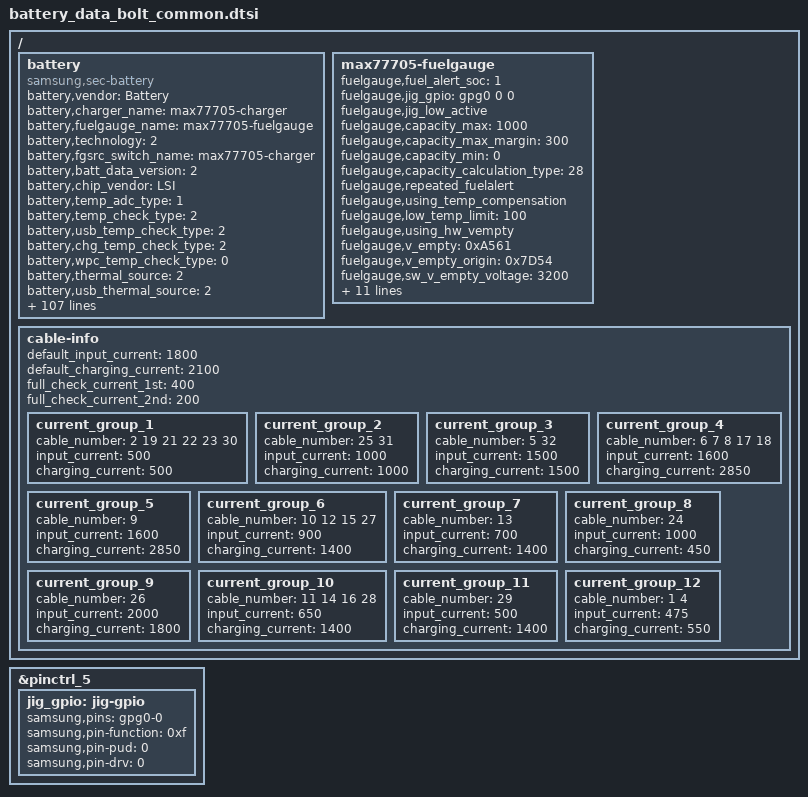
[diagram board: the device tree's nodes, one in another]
/*
 * SAMSUNG UNIVERSAL9820 board device tree source
 *
 * Copyright (c) 2018 Samsung Electronics Co., Ltd.
 *		http://www.samsung.com
 *
 * This program is free software; you can redistribute it and/or modify
 * it under the terms of the GNU General Public License version 2 as
 * published by the Free Software Foundation.
 */

/ {
	fragment@battery {
		target-path = "/";
		__overlay__ {
			battery {
				status = "okay";
				compatible = "samsung,sec-battery";

				pinctrl-names = "default";
				/* battery,irq_gpio = <&gpa1 6 0>; */

				battery,vendor = "Battery";
				battery,charger_name = "max77705-charger";
				battery,fuelgauge_name = "max77705-fuelgauge";
				battery,technology = <2>; /* POWER_SUPPLY_TECHNOLOGY_LION */
				battery,fgsrc_switch_name = "max77705-charger"; /* Fuelgauge voltage source */

				battery,batt_data_version = <2>;

				battery,chip_vendor = "LSI";
				battery,temp_adc_type = <1>; /* SEC_BATTERY_ADC_TYPE_AP */

				battery,temp_check_type = <2>; /* SEC_BATTERY_TEMP_CHECK_NONE */
				battery,usb_temp_check_type = <2>;
				battery,chg_temp_check_type = <2>;
				battery,wpc_temp_check_type = <0>;

				battery,thermal_source = <2>; /* SEC_BATTERY_THERMAL_SOURCE_ADC */
				battery,usb_thermal_source = <2>; /* SEC_BATTERY_THERMAL_SOURCE_ADC */
				battery,chg_thermal_source = <2>; /* SEC_BATTERY_THERMAL_SOURCE_ADC */

				battery,polling_time = <10 30 30 30 3600>;

				battery,temp_table_adc = <262 311 370 436 509 591 695 818 877 1058 1224 1404
								1604 1814 2044 2288 2493 2675 2888 3036 3387 3525 3596>;
				battery,temp_table_data = <900 850 800 750 700 650 600 550 500 450 400 350
								300 250 200 150 100 50 0 (-50) (-100) (-150) (-200)>;

				battery,usb_temp_table_adc = <267 319 379 449 527 615 724 850 946 1126 1304 1484
								1684 1894 2137 2362 2566 2735 2947 3042 3297 3419 3484>;
				battery,usb_temp_table_data = <900 850 800 750 700 650 600 550 500 450 400 350
								300 250 200 150 100 50 0 (-50) (-100) (-150) (-200)>;

				battery,chg_temp_table_adc = <255 303 362 428 500 579 679 801 898 1082 1344 1524
								1724 1934 2088 2336 2536 2715 2932 3065 3357 3495 3584>;
				battery,chg_temp_table_data = <900 850 800 750 700 650 600 550 500 450 400 350
								300 250 200 150 100 50 0 (-50) (-100) (-150) (-200)>;

				battery,adc_check_count = <5>;

				battery,cable_check_type = <4>; /* SEC_BATTERY_CABLE_CHECK_PSY */
				battery,cable_source_type = <1>; /* SEC_BATTERY_CABLE_SOURCE_EXTERNAL */
				battery,polling_type = <1>; /* SEC_BATTERY_MONITOR_ALARM */
				battery,monitor_initial_count = <0>;

				battery,battery_check_type = <0>; /* SEC_BATTERY_CHECK_NONE */
				battery,check_count = <0>;
				battery,check_adc_max = <1440>;
				battery,check_adc_min = <0>;

				battery,ovp_uvlo_check_type = <3>; /* SEC_BATTERY_OVP_UVLO_CHGPOLLING */

				battery,temp_check_count = <1>;
				battery,temp_highlimit_threshold_event = <800>;
				battery,temp_highlimit_recovery_event = <750>;
				battery,temp_high_threshold_event = <500>;
				battery,temp_high_recovery_event = <450>;
				battery,temp_low_threshold_event = <0>;
				battery,temp_low_recovery_event = <50>;
				battery,temp_highlimit_threshold_normal = <800>;
				battery,temp_highlimit_recovery_normal = <750>;
				battery,temp_high_threshold_normal = <500>;
				battery,temp_high_recovery_normal = <450>;
				battery,temp_low_threshold_normal = <0>;
				battery,temp_low_recovery_normal = <50>;
				battery,temp_highlimit_threshold_lpm = <800>;
				battery,temp_highlimit_recovery_lpm = <750>;
				battery,temp_high_threshold_lpm = <500>;
				battery,temp_high_recovery_lpm = <450>;
				battery,temp_low_threshold_lpm = <0>;
				battery,temp_low_recovery_lpm = <50>;
				battery,full_check_type = <7>; /* SEC_BATTERY_FULLCHARGED_CHGPSY */
				battery,full_check_type_2nd = <7>; /* SEC_BATTERY_FULLCHARGED_CHGPSY */
				battery,full_check_count = <1>;
				battery,chg_gpio_full_check = <0>;
				battery,chg_polarity_full_check = <1>;

				battery,chg_high_temp = <460>;
				battery,chg_high_temp_recovery = <440>;
				battery,chg_input_limit_current = <1000>;
				battery,chg_charging_limit_current = <1500>;

				battery,mix_high_temp = <420>;
				battery,mix_high_chg_temp = <500>;
				battery,mix_high_temp_recovery = <390>;

				/* SEC_BATTERY_FULL_CONDITION_NOTIMEFULL | SEC_BATTERY_FULL_CONDITION_VCELL */
				battery,full_condition_type = <9>;
				battery,full_condition_soc = <93>;
				battery,full_condition_vcell = <4250>;

				battery,recharge_check_count = <1>;
				battery,recharge_condition_type = <4>; /* SEC_BATTERY_RECHARGE_CONDITION_VCELL */
				battery,recharge_condition_soc = <98>;
				battery,recharge_condition_vcell = <4280>;

				battery,charging_total_time = <14400>;
				battery,hv_charging_total_time = <10800>;
				battery,normal_charging_total_time = <18000>;
				battery,usb_charging_total_time = <36000>;
				battery,recharging_total_time = <5400>;
				battery,charging_reset_time = <0>;

				battery,chg_float_voltage = <4350>;

				battery,swelling_high_temp_block = <410>;
				battery,swelling_high_temp_recov = <390>;
				battery,swelling_low_temp_block_1st = <150>;
				battery,swelling_low_temp_recov_1st = <200>;
				battery,swelling_low_temp_block_2nd = <50>;
				battery,swelling_low_temp_recov_2nd = <100>;

				battery,swelling_low_temp_current = <950>;	/* 0.3C */
				battery,swelling_low_temp_current_2nd = <950>;	/* 0.1C */
				battery,swelling_low_temp_topoff = <200>;	/* 0.05C */
				battery,swelling_high_temp_current = <1400>;	/* 0.45C */
				battery,swelling_high_temp_topoff = <200>;	/* 0.05C */

				battery,swelling_drop_float_voltage = <4150>;
				battery,swelling_high_rechg_voltage = <4000>;
				battery,swelling_low_rechg_voltage = <4000>;
				battery,wa_float_voltage = <4050>;

				battery,siop_input_limit_current = <1200>;
				battery,siop_charging_limit_current = <1000>;
				battery,siop_hv_input_limit_current = <500>;
				battery,siop_hv_charging_limit_current = <1000>;

				battery,ttf_hv_charge_current = <2850>;

				battery,pd_charging_charge_power = <15000>;
				battery,max_charging_current = <2850>;
				battery,battery_full_capacity = <4000>;

				/* cycle, chg_float_voltage, recharge_condition_vcell, full_condition_vcell, full_condition_soc */
				battery,age_data = <0 4350 4280 4250 93
					300 4330 4260 4230 92
					400 4310 4240 4210 91
					700 4290 4220 4190 90
					1000 4240 4170 4140 89>;

				battery,pre_afc_input_current = <500>; /* mA */
				battery,prepare_ta_delay = <0>; /* msec */

				battery,max_input_voltage = <9000>; /* mV */
				battery,max_input_current = <3000>;  /* mA */

				battery,enable_sysovlo_irq;

				battery,standard_curr = <2850>;
				battery,expired_time = <10800>;
				battery,recharging_expired_time = <5400>;

				battery,cisd_max_voltage_thr = <4400>; /* battery ovp detection voltage */

				battery,cisd_alg_index = <7>;

				io-channels = <&exynos_adc 4>, <&exynos_adc 3>, <&exynos_adc 1>;
				io-channel-names = "adc-temp", "adc-chg-temp", "adc-usb-temp";
				#io-channel-cells = <5>;
				io-channel-ranges;
			};

			max77705-fuelgauge {
				/* for 4000mAh battery */
				status = "okay";
				fuelgauge,fuel_alert_soc = <1>;
				fuelgauge,jig_gpio = <&gpg0 0 0>;
				fuelgauge,jig_low_active;
				fuelgauge,capacity_max = <1000>;
				fuelgauge,capacity_max_margin = <300>;
				fuelgauge,capacity_min = <0>;
				fuelgauge,capacity_calculation_type = <28>;
				fuelgauge,repeated_fuelalert;
				fuelgauge,using_temp_compensation;
				fuelgauge,low_temp_limit = <100>;
				fuelgauge,using_hw_vempty;
				fuelgauge,v_empty = <0xA561>; /* Empty: 3350mV, Recover: 3920mV */
				fuelgauge,v_empty_origin = <0x7D54>; /* Empty: 2500mV, Recover: 3360mV */
				fuelgauge,sw_v_empty_voltage = <3200>;
				fuelgauge,sw_v_empty_voltage_cisd = <3100>;
				fuelgauge,sw_v_empty_recover_voltage = <3480>;
				fuelgauge,qrtable20 = <0x1104>;
				fuelgauge,qrtable30 = <0x0A04>;
				fuelgauge,fg_resistor = <2>;
				fuelgauge,capacity = <0x0EE6>;
				/*fuelgauge,auto_discharge_en;*/
				fuelgauge,discharge_temp_threshold = <600>;
				fuelgauge,discharge_volt_threshold = <4200>;
				fuelgauge,ttf_capacity = <4000>;
				fuelgauge,cv_data = <
					2488	829	1809
					2409	832	1796
					2327	837	1769
					2272	840	1743
					2182	846	1721
					2104	850	1690
					2038	854	1670
					1950	859	1640
					1904	861	1622
					1838	865	1594
					1797	867	1576
					1749	870	1560
					1703	873	1531
					1683	873	1525
					1667	875	1515
					1660	875	1512
					1653	876	1509
					1615	878	1502
					1580	880	1483
					1553	881	1463
					1544	882	1458
					1520	883	1451
					1477	886	1424
					1431	888	1409
					1396	891	1383
					1347	894	1361
					1299	896	1332
					1267	898	1315
					1231	902	1288
					1202	904	1263
					1148	906	1243
					1109	909	1213
					1067	911	1185
					1031	914	1156
					1013	915	1140
					975	917	1111
					961	919	1084
					921	921	1064
					892	923	1038
					887	923	1019
					863	925	1004
					833	927	976
					808	929	946
					787	930	918
					780	931	904
					764	932	895
					744	934	864
					730	935	846
					715	936	828
					693	937	800
					681	938	783
					666	940	752
					651	941	735
					640	942	712
					628	945	697
					622	946	679
					618	947	664
					600	950	646
					596	951	627
					589	953	614
					584	953	601
					576	956	572
					577	957	553
					562	958	535
					511	968	506
					505	969	487
					493	971	464
					492	972	435
					484	973	417
					480	975	398
					474	976	380
					470	977	364
					462	977	355
					456	978	336
					452	979	329
					446	981	303
					437	982	282
					429	984	255
					423	985	242
					422	986	229
					414	987	211
					411	988	199
					405	989	191
					397	990	171
					391	991	140
					387	992	126
					384	993	107
					372	995	84
					364	997	54
					356	998	26
					356	998	13
					0	1000	0
					>;
			};

			/* sec_battery_cable
			 *   0	UNKNOWN,
			 *   1	NONE,
			 *   2	PREPARE_TA,
			 *   3	TA,
			 *   4	USB,
			 *   5	USB_CDP,
			 *   6	9V_TA,
			 *   7	9V_ERR,
			 *   8	9V_UNKNOWN,
			 *   9	12V_TA,
			 *  10	WIRELESS,
			 *  11	HV_WIRELESS,
			 *  12	PMA_WIRELESS,
			 *  13	WIRELESS_PACK,
			 *  14	WIRELESS_HV_PACK,
			 *  15	WIRELESS_STAND,
			 *  16	WIRELESS_HV_STAND,
			 *  17	QC20,
			 *  18	QC30,
			 *  19	PDIC,
			 *  20	UARTOFF,
			 *  21	OTG,
			 *  22	LAN_HUB,
			 *  23	POWER_SHARING,
			 *  24	HMT_CONNECTED,
			 *  25	HMT_CHARGE,
			 *  26	HV_TA_CHG_LIMIT,
			 *  27	WIRELESS_VEHICLE,
			 *  28	WIRELESS_HV_VEHICLE,
			 *  29	PREPARE_WIRELESS_HV,
			 *  30	TIMEOUT,
			 *  31	SMART_OTG,
			 *  32	SMART_NOTG,
			 *  33	CABLE_MAX,
			 */

			cable-info {
				default_input_current = <1800>;
				default_charging_current = <2100>;
				full_check_current_1st = <400>;
				full_check_current_2nd = <200>;

				current_group_1 {
					cable_number = <2 19 21 22 23 30>;
					input_current = <500>;
					charging_current = <500>;
				};
				current_group_2 {
					cable_number = <25 31>;
					input_current = <1000>;
					charging_current = <1000>;
				};
				current_group_3 {
					cable_number = <5 32>;
					input_current = <1500>;
					charging_current = <1500>;
				};
				current_group_4 {
					cable_number = <6 7 8 17 18>;
					input_current = <1600>;
					charging_current = <2850>;
				};
				current_group_5 {
					cable_number = <9>;
					input_current = <1600>;
					charging_current = <2850>;
				};
				current_group_6 {
					cable_number = <10 12 15 27>;
					input_current = <900>;
					charging_current = <1400>;
				};
				current_group_7 {
					cable_number = <13>;
					input_current = <700>;
					charging_current = <1400>;
				};
				current_group_8 {
					cable_number = <24>;
					input_current = <1000>;
					charging_current = <450>;
				};
				current_group_9 {
					cable_number = <26>;
					input_current = <2000>;
					charging_current = <1800>;
				};
				current_group_10 {
					cable_number = <11 14 16 28>;
					input_current = <650>;
					charging_current = <1400>;
				};
				current_group_11 {
					cable_number = <29>;
					input_current = <500>;
					charging_current = <1400>;
				};
				current_group_12 {
					cable_number = <1 4>;
					input_current = <475>;
					charging_current = <550>;
				};
			};
		}; /* end of __overlay__ */
	}; /* end of fragment */
};

&pinctrl_5 {
	jig_gpio: jig-gpio {
		samsung,pins = "gpg0-0";
		samsung,pin-function = <0xf>;
		samsung,pin-pud = <0>;
		samsung,pin-drv = <0>;
	};
};

